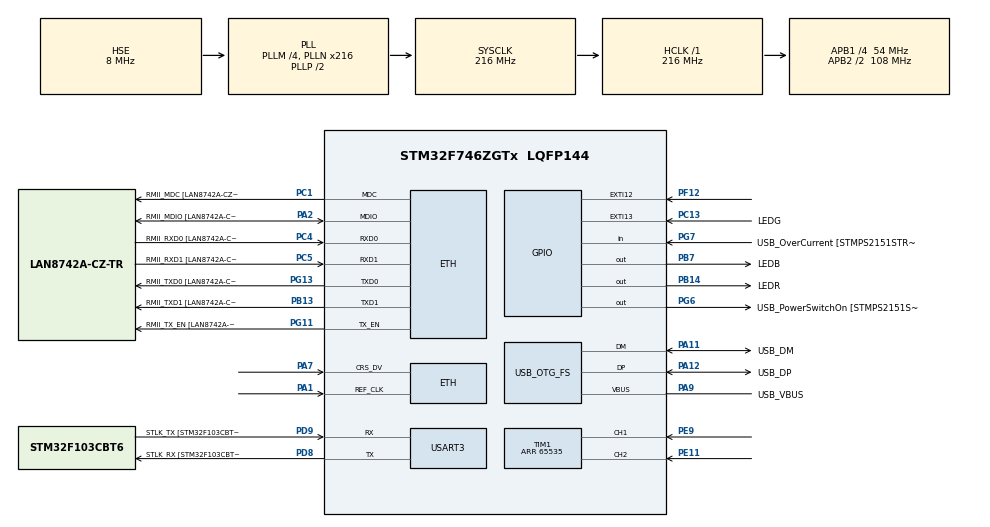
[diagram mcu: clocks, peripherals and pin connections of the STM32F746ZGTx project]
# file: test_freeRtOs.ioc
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CORTEX_M7.ART_ACCLERATOR_ENABLE=1
CORTEX_M7.CPU_DCache=Enabled
CORTEX_M7.CPU_ICache=Enabled
CORTEX_M7.MPU_Control=__NULL
CORTEX_M7.PREFETCH_ENABLE=1
Dma.Request0=USART3_RX
Dma.USART3_RX.0.Direction=DMA_PERIPH_TO_MEMORY
Dma.USART3_RX.0.FIFOMode=DMA_FIFOMODE_DISABLE
Dma.USART3_RX.0.Instance=DMA1_Stream1
Dma.USART3_RX.0.MemDataAlignment=DMA_MDATAALIGN_BYTE
Dma.USART3_RX.0.MemInc=DMA_MINC_ENABLE
Dma.USART3_RX.0.Mode=DMA_NORMAL
Dma.USART3_RX.0.PeriphDataAlignment=DMA_PDATAALIGN_BYTE
Dma.USART3_RX.0.PeriphInc=DMA_PINC_DISABLE
Dma.USART3_RX.0.Priority=DMA_PRIORITY_LOW
ETH.MediaInterface=ETH_MEDIA_INTERFACE_RMII
ETH.PhyAddress=0
FREERTOS.HEAP_NUMBER=3
FREERTOS.INCLUDE_vTaskDelayUntil=1
FREERTOS.MEMORY_ALLOCATION=0
FREERTOS.Queues01=RxUartQueue,1,uint16_t,0,Dynamic,NULL,NULL
FREERTOS.Tasks01=idle,-3,512,idle_start,Default,NULL,Dynamic,NULL,NULL;asserv_task,3,512,start_asserv_task,As external,NULL,Dynamic,NULL,NULL;background_task,-2,512,start_background_task,As external,NULL,Dynamic,NULL,NULL;io_task,1,512,start_io_task,As external,NULL,Dynamic,NULL,NULL
FREERTOS.configCHECK_FOR_STACK_OVERFLOW=2
FREERTOS.configIDLE_SHOULD_YIELD=0
FREERTOS.configTOTAL_HEAP_SIZE=131072
LWIP.CHECKSUM_BY_HARDWARE=1
LWIP.CHECKSUM_CHECK_ICMP=1
LWIP.CHECKSUM_CHECK_ICMP6=1
LWIP.CHECKSUM_CHECK_IP=1
LWIP.CHECKSUM_CHECK_UDP=1
LWIP.CHECKSUM_GEN_ICMP=1
LWIP.CHECKSUM_GEN_ICMP6=1
LWIP.CHECKSUM_GEN_IP=1
LWIP.CHECKSUM_GEN_UDP=1
LWIP.ICMP_DEBUG=LWIP_DBG_ON
LWIP.IP_ADDRESS=192.168.010.002
LWIP.LWIP_DBG_MIN_LEVEL=LWIP_DBG_LEVEL_WARNING
LWIP.LWIP_DHCP=0
LWIP.LWIP_TCP=0
LWIP.MEMP_NUM_RAW_PCB=2
LWIP.MEMP_NUM_TCP_PCB=1
LWIP.MEMP_NUM_TCP_PCB_LISTEN=2
LWIP.MEMP_NUM_UDP_PCB=2
LWIP.MEM_SIZE=4096
LWIP.NETMASK_ADDRESS=255.255.255.000
LWIP.Version=v2.0.3_Cube
Mcu.Family=STM32F7
Mcu.Name=STM32F746ZGTx
Mcu.Package=LQFP144
NVIC.DMA1_Stream1_IRQn=true\:5\:0\:false\:false\:true\:true\:false
NVIC.ETH_IRQn=true\:5\:0\:false\:false\:true\:true\:true
NVIC.ETH_WKUP_IRQn=true\:5\:0\:false\:false\:true\:true\:true
NVIC.OTG_FS_IRQn=true\:5\:0\:false\:false\:true\:true\:false
NVIC.PriorityGroup=NVIC_PRIORITYGROUP_4
NVIC.TIM1_TRG_COM_TIM11_IRQn=true\:0\:0\:false\:false\:true\:false\:false
NVIC.TimeBase=TIM1_TRG_COM_TIM11_IRQn
NVIC.TimeBaseIP=TIM11
NVIC.USART3_IRQn=true\:5\:0\:false\:false\:true\:true\:true
PA1.Mode=RMII
PA1.Signal=ETH_REF_CLK
PA10.GPIO_Label=USB_ID
PA10.Signal=USB_OTG_FS_ID
PA11.GPIO_Label=USB_DM
PA11.Mode=Host_Only
PA11.Signal=USB_OTG_FS_DM
PA12.GPIO_Label=USB_DP
PA12.Mode=Host_Only
PA12.Signal=USB_OTG_FS_DP
PA13.GPIO_Label=TMS
PA13.Mode=Serial_Wire
PA13.Signal=SYS_JTMS-SWDIO
PA14.GPIO_Label=TCK
PA14.Mode=Serial_Wire
PA14.Signal=SYS_JTCK-SWCLK
PA2.GPIO_Label=RMII_MDIO [LAN8742A-CZ-TR_MDIO]
PA2.Mode=RMII
PA2.Signal=ETH_MDIO
PA7.Mode=RMII
PA7.Signal=ETH_CRS_DV
PA8.GPIO_Label=USB_SOF [TP1]
PA8.Signal=USB_OTG_FS_SOF
PA9.GPIO_Label=USB_VBUS
PA9.Mode=Activate_VBUS
PA9.Signal=USB_OTG_FS_VBUS
PB13.GPIO_Label=RMII_TXD1 [LAN8742A-CZ-TR_TXD1]
PB13.Mode=RMII
PB13.Signal=ETH_TXD1
PB14.GPIO_Label=LEDR
PB14.Signal=GPIO_Output
PB3.GPIO_Label=SW0
PB3.Signal=SYS_JTDO-SWO
PB7.GPIO_Label=LEDB
PB7.Signal=GPIO_Output
PC0.Signal=FMC_SDNWE
PC1.GPIO_Label=RMII_MDC [LAN8742A-CZ-TR_MDC]
PC1.Mode=RMII
PC1.Signal=ETH_MDC
PC13.GPIO_Label=LEDG
PC13.Signal=GPXTI13
PC14/OSC32_IN.Mode=LSE-External-Oscillator
PC14/OSC32_IN.Signal=RCC_OSC32_IN
PC15/OSC32_OUT.Mode=LSE-External-Oscillator
PC15/OSC32_OUT.Signal=RCC_OSC32_OUT
PC4.GPIO_Label=RMII_RXD0 [LAN8742A-CZ-TR_RXD0]
PC4.Mode=RMII
PC4.Signal=ETH_RXD0
PC5.GPIO_Label=RMII_RXD1 [LAN8742A-CZ-TR_RXD1]
PC5.Mode=RMII
PC5.Signal=ETH_RXD1
PD8.GPIO_Label=STLK_RX [STM32F103CBT6_PA3]
PD8.Mode=Asynchronous
PD8.Signal=USART3_TX
PD9.GPIO_Label=STLK_TX [STM32F103CBT6_PA2]
PD9.Mode=Asynchronous
PD9.Signal=USART3_RX
PE11.GPIO_PuPd=GPIO_PULLUP
PE11.GPIO_Speed=GPIO_SPEED_FREQ_VERY_HIGH
PE11.Signal=S_TIM1_CH2
PE9.GPIO_PuPd=GPIO_PULLUP
PE9.GPIO_Speed=GPIO_SPEED_FREQ_VERY_HIGH
PE9.Signal=S_TIM1_CH1
PF12.Signal=GPXTI12
PG11.GPIO_Label=RMII_TX_EN [LAN8742A-CZ-TR_TXEN]
PG11.Mode=RMII
PG11.Signal=ETH_TX_EN
PG13.GPIO_Label=RMII_TXD0 [LAN8742A-CZ-TR_TXD0]
PG13.Mode=RMII
PG13.Signal=ETH_TXD0
PG6.GPIO_Label=USB_PowerSwitchOn [STMPS2151STR_EN]
PG6.Signal=GPIO_Output
PG7.GPIO_Label=USB_OverCurrent [STMPS2151STR_FAULT]
PG7.Signal=GPIO_Input
PH0/OSC_IN.GPIO_Label=MCO [STM32F103CBT6_PA8]
PH0/OSC_IN.Mode=HSE-External-Oscillator
PH0/OSC_IN.Signal=RCC_OSC_IN
PH1/OSC_OUT.Mode=HSE-External-Oscillator
PH1/OSC_OUT.Signal=RCC_OSC_OUT
ProjectManager.HeapSize=0x200
ProjectManager.StackSize=0x400
ProjectManager.TargetToolchain=Makefile
RCC.48MHZClocksFreq_Value=24000000
RCC.AHBFreq_Value=216000000
RCC.APB1CLKDivider=RCC_HCLK_DIV4
RCC.APB1Freq_Value=54000000
RCC.APB1TimFreq_Value=108000000
RCC.APB2CLKDivider=RCC_HCLK_DIV2
RCC.APB2Freq_Value=108000000
RCC.APB2TimFreq_Value=216000000
RCC.CortexFreq_Value=216000000
RCC.HCLKFreq_Value=216000000
RCC.HSE_VALUE=8000000
RCC.HSI_VALUE=16000000
RCC.PLLM=4
RCC.PLLMUL=RCC_PLL_MUL9
RCC.PLLN=216
RCC.PLLQ=9
RCC.PRESCALERUSB=RCC_USBCLKSOURCE_PLL_DIV1_5
RCC.SYSCLKFreq_VALUE=216000000
RCC.SYSCLKSource=RCC_SYSCLKSOURCE_PLLCLK
RCC.SYSCLKSourceVirtual=RCC_SYSCLKSOURCE_PLLCLK
RCC.USBFreq_Value=48000000
RCC.VCOOutputFreq_Value=432000000
SH.FMC_SDNWE.0=FMC_SDNWE
SH.S_TIM1_CH1.0=TIM1_CH1,Encoder_Interface
SH.S_TIM1_CH2.0=TIM1_CH2,Encoder_Interface
TIM1.AutoReloadPreload=TIM_AUTORELOAD_PRELOAD_DISABLE
TIM1.EncoderMode=TIM_ENCODERMODE_TI12
TIM1.IC1Filter=15
TIM1.IC2Filter=15
TIM1.Period=65535
TIM1.RepetitionCounter=65535
USART3.VirtualMode-Asynchronous=VM_ASYNC
USART3.WordLength=WORDLENGTH_8B
USB_HOST.BSP.number=1
USB_HOST.USBH_HandleTypeDef-MSC_FS=hUsbHostFS
USB_HOST.VirtualModeFS=Msc
USB_HOST0.BSP.STBoard=false
USB_HOST0.BSP.api=UnknownBspDriver
USB_HOST0.BSP.i2caddr=0
USB_HOST0.BSP.i2creg=0
USB_HOST0.BSP.instance=PB14
USB_HOST0.BSP.ip=GPIO
USB_HOST0.BSP.mode=Output
USB_HOST0.BSP.name=Drive_VBUS_FS
USB_HOST0.BSP.solution=PB14
USB_OTG_FS.VirtualMode=Host_Only
USB_OTG_FS.phy_itface=HCD_PHY_EMBEDDED
VP_FATFS_VS_USB.Mode=USB
VP_FREERTOS_VS_ENABLE.Mode=Enabled
VP_LWIP_VS_Enabled.Mode=Enabled
VP_SYS_VS_tim11.Mode=TIM11
VP_TIM1_VS_OPM.Mode=OPM_bit
VP_USB_HOST_VS_USB_HOST_MSC_FS.Mode=MSC_FS
board=NUCLEO-F746ZG

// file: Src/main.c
/**
  ******************************************************************************
  * @file           : main.c
  * @brief          : Main program body
  ******************************************************************************
  * This notice applies to any and all portions of this file
  * that are not between comment pairs USER CODE BEGIN and
  * USER CODE END. Other portions of this file, whether
  * inserted by the user or by software development tools
  * are owned by their respective copyright owners.
  *
  * Copyright (c) 2018 STMicroelectronics International N.V.
  * All rights reserved.
  *
  * Redistribution and use in source and binary forms, with or without
  * modification, are permitted, provided that the following conditions are met:
  *
  * 1. Redistribution of source code must retain the above copyright notice,
  *    this list of conditions and the following disclaimer.
  * 2. Redistributions in binary form must reproduce the above copyright notice,
  *    this list of conditions and the following disclaimer in the documentation
  *    and/or other materials provided with the distribution.
  * 3. Neither the name of STMicroelectronics nor the names of other
  *    contributors to this software may be used to endorse or promote products
  *    derived from this software without specific written permission.
  * 4. This software, including modifications and/or derivative works of this
  *    software, must execute solely and exclusively on microcontroller or
  *    microprocessor devices manufactured by or for STMicroelectronics.
  * 5. Redistribution and use of this software other than as permitted under
  *    this license is void and will automatically terminate your rights under
  *    this license.
  *
  * THIS SOFTWARE IS PROVIDED BY STMICROELECTRONICS AND CONTRIBUTORS "AS IS"
  * AND ANY EXPRESS, IMPLIED OR STATUTORY WARRANTIES, INCLUDING, BUT NOT
  * LIMITED TO, THE IMPLIED WARRANTIES OF MERCHANTABILITY, FITNESS FOR A
  * PARTICULAR PURPOSE AND NON-INFRINGEMENT OF THIRD PARTY INTELLECTUAL PROPERTY
  * RIGHTS ARE DISCLAIMED TO THE FULLEST EXTENT PERMITTED BY LAW. IN NO EVENT
  * SHALL STMICROELECTRONICS OR CONTRIBUTORS BE LIABLE FOR ANY DIRECT, INDIRECT,
  * INCIDENTAL, SPECIAL, EXEMPLARY, OR CONSEQUENTIAL DAMAGES (INCLUDING, BUT NOT
  * LIMITED TO, PROCUREMENT OF SUBSTITUTE GOODS OR SERVICES; LOSS OF USE, DATA,
  * OR PROFITS; OR BUSINESS INTERRUPTION) HOWEVER CAUSED AND ON ANY THEORY OF
  * LIABILITY, WHETHER IN CONTRACT, STRICT LIABILITY, OR TORT (INCLUDING
  * NEGLIGENCE OR OTHERWISE) ARISING IN ANY WAY OUT OF THE USE OF THIS SOFTWARE,
  * EVEN IF ADVISED OF THE POSSIBILITY OF SUCH DAMAGE.
  *
  ******************************************************************************
  */
#include "main.h"
#include "stm32f7xx_hal.h"
#include "cmsis_os.h"
#include "dma.h"
#include "lwip.h"
#include "tim.h"
#include "usart.h"
#include "usb_otg.h"
#include "gpio.h"

/* USER CODE BEGIN Includes */
#include "usart.h"
/* USER CODE END Includes */

/* USER CODE BEGIN PV */
/* Private variables ---------------------------------------------------------*/

/* USER CODE END PV */

void SystemClock_Config(void);
void MX_FREERTOS_Init(void);

/* USER CODE BEGIN PFP */
/* Private function prototypes -----------------------------------------------*/

/* USER CODE END PFP */

int main(void)
{

  /* Enable I-Cache-------------------------------------------------------------*/
  SCB_EnableICache();

  /* Enable D-Cache-------------------------------------------------------------*/
  SCB_EnableDCache();

  /* MCU Configuration----------------------------------------------------------*/

  /* Reset of all peripherals, Initializes the Flash interface and the Systick. */
  HAL_Init();

  /* Configure the system clock */
  SystemClock_Config();

  /* Initialize all configured peripherals */
  MX_GPIO_Init();
  MX_DMA_Init();
  MX_USART3_UART_Init();
  MX_TIM1_Init();
  MX_USB_OTG_FS_PCD_Init();
  /* USER CODE BEGIN 2 */

//  __HAL_UART_ENABLE_IT(&huart3, UART_IT_RXNE);
  __HAL_UART_ENABLE_IT(&huart3, UART_IT_TC);

  HAL_NVIC_EnableIRQ(ETH_IRQn);

  /* Enable ETHERNET clock  */
  __HAL_RCC_ETH_CLK_ENABLE();
  __HAL_RCC_ETHMAC_CLK_ENABLE();
  __HAL_RCC_ETHMACTX_CLK_ENABLE();
  __HAL_RCC_ETHMACRX_CLK_ENABLE();

  /* USER CODE END 2 */

  /* Call init function for freertos objects (in freertos.c) */
  MX_FREERTOS_Init();

  /* Start scheduler */
  osKernelStart();

  /* We should never get here as control is now taken by the scheduler */

  /* Infinite loop */
  while (1)
  {

  }

}

void SystemClock_Config(void)
{

  RCC_OscInitTypeDef RCC_OscInitStruct;
  RCC_ClkInitTypeDef RCC_ClkInitStruct;
  RCC_PeriphCLKInitTypeDef PeriphClkInitStruct;

    /**Configure the main internal regulator output voltage
    */
  __HAL_RCC_PWR_CLK_ENABLE();

  __HAL_PWR_VOLTAGESCALING_CONFIG(PWR_REGULATOR_VOLTAGE_SCALE1);

    /**Initializes the CPU, AHB and APB busses clocks
    */
  RCC_OscInitStruct.OscillatorType = RCC_OSCILLATORTYPE_HSE;
  RCC_OscInitStruct.HSEState = RCC_HSE_BYPASS;
  RCC_OscInitStruct.PLL.PLLState = RCC_PLL_ON;
  RCC_OscInitStruct.PLL.PLLSource = RCC_PLLSOURCE_HSE;
  RCC_OscInitStruct.PLL.PLLM = 4;
  RCC_OscInitStruct.PLL.PLLN = 216;
  RCC_OscInitStruct.PLL.PLLP = RCC_PLLP_DIV2;
  RCC_OscInitStruct.PLL.PLLQ = 9;
  if (HAL_RCC_OscConfig(&RCC_OscInitStruct) != HAL_OK)
  {
    _Error_Handler(__FILE__, __LINE__);
  }

    /**Activate the Over-Drive mode
    */
  if (HAL_PWREx_EnableOverDrive() != HAL_OK)
  {
    _Error_Handler(__FILE__, __LINE__);
  }

    /**Initializes the CPU, AHB and APB busses clocks
    */
  RCC_ClkInitStruct.ClockType = RCC_CLOCKTYPE_HCLK|RCC_CLOCKTYPE_SYSCLK
                              |RCC_CLOCKTYPE_PCLK1|RCC_CLOCKTYPE_PCLK2;
  RCC_ClkInitStruct.SYSCLKSource = RCC_SYSCLKSOURCE_PLLCLK;
  RCC_ClkInitStruct.AHBCLKDivider = RCC_SYSCLK_DIV1;
  RCC_ClkInitStruct.APB1CLKDivider = RCC_HCLK_DIV4;
  RCC_ClkInitStruct.APB2CLKDivider = RCC_HCLK_DIV2;

  if (HAL_RCC_ClockConfig(&RCC_ClkInitStruct, FLASH_LATENCY_7) != HAL_OK)
  {
    _Error_Handler(__FILE__, __LINE__);
  }

  PeriphClkInitStruct.PeriphClockSelection = RCC_PERIPHCLK_USART3|RCC_PERIPHCLK_CLK48;
  PeriphClkInitStruct.Usart3ClockSelection = RCC_USART3CLKSOURCE_PCLK1;
  PeriphClkInitStruct.Clk48ClockSelection = RCC_CLK48SOURCE_PLL;
  if (HAL_RCCEx_PeriphCLKConfig(&PeriphClkInitStruct) != HAL_OK)
  {
    _Error_Handler(__FILE__, __LINE__);
  }

    /**Configure the Systick interrupt time
    */
  HAL_SYSTICK_Config(HAL_RCC_GetHCLKFreq()/1000);

    /**Configure the Systick
    */
  HAL_SYSTICK_CLKSourceConfig(SYSTICK_CLKSOURCE_HCLK);

  /* SysTick_IRQn interrupt configuration */
  HAL_NVIC_SetPriority(SysTick_IRQn, 15, 0);
}

void HAL_TIM_PeriodElapsedCallback(TIM_HandleTypeDef *htim)
{
  if (htim->Instance == TIM11) {
    HAL_IncTick();
  }
}

void _Error_Handler(char *file, int line)
{
  while(1)
  {
  }
}

/************************ (C) COPYRIGHT STMicroelectronics *****END OF FILE****/

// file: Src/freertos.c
/**
  ******************************************************************************
  * File Name          : freertos.c
  * Description        : Code for freertos applications
  ******************************************************************************
  * This notice applies to any and all portions of this file
  * that are not between comment pairs USER CODE BEGIN and
  * USER CODE END. Other portions of this file, whether
  * inserted by the user or by software development tools
  * are owned by their respective copyright owners.
  *
  * Copyright (c) 2018 STMicroelectronics International N.V.
  * All rights reserved.
  *
  * Redistribution and use in source and binary forms, with or without
  * modification, are permitted, provided that the following conditions are met:
  *
  * 1. Redistribution of source code must retain the above copyright notice,
  *    this list of conditions and the following disclaimer.
  * 2. Redistributions in binary form must reproduce the above copyright notice,
  *    this list of conditions and the following disclaimer in the documentation
  *    and/or other materials provided with the distribution.
  * 3. Neither the name of STMicroelectronics nor the names of other
  *    contributors to this software may be used to endorse or promote products
  *    derived from this software without specific written permission.
  * 4. This software, including modifications and/or derivative works of this
  *    software, must execute solely and exclusively on microcontroller or
  *    microprocessor devices manufactured by or for STMicroelectronics.
  * 5. Redistribution and use of this software other than as permitted under
  *    this license is void and will automatically terminate your rights under
  *    this license.
  *
  * THIS SOFTWARE IS PROVIDED BY STMICROELECTRONICS AND CONTRIBUTORS "AS IS"
  * AND ANY EXPRESS, IMPLIED OR STATUTORY WARRANTIES, INCLUDING, BUT NOT
  * LIMITED TO, THE IMPLIED WARRANTIES OF MERCHANTABILITY, FITNESS FOR A
  * PARTICULAR PURPOSE AND NON-INFRINGEMENT OF THIRD PARTY INTELLECTUAL PROPERTY
  * RIGHTS ARE DISCLAIMED TO THE FULLEST EXTENT PERMITTED BY LAW. IN NO EVENT
  * SHALL STMICROELECTRONICS OR CONTRIBUTORS BE LIABLE FOR ANY DIRECT, INDIRECT,
  * INCIDENTAL, SPECIAL, EXEMPLARY, OR CONSEQUENTIAL DAMAGES (INCLUDING, BUT NOT
  * LIMITED TO, PROCUREMENT OF SUBSTITUTE GOODS OR SERVICES; LOSS OF USE, DATA,
  * OR PROFITS; OR BUSINESS INTERRUPTION) HOWEVER CAUSED AND ON ANY THEORY OF
  * LIABILITY, WHETHER IN CONTRACT, STRICT LIABILITY, OR TORT (INCLUDING
  * NEGLIGENCE OR OTHERWISE) ARISING IN ANY WAY OUT OF THE USE OF THIS SOFTWARE,
  * EVEN IF ADVISED OF THE POSSIBILITY OF SUCH DAMAGE.
  *
  ******************************************************************************
  */

#include "FreeRTOS.h"
#include "task.h"
#include "cmsis_os.h"

osThreadId idleHandle;
osThreadId asserv_taskHandle;
osThreadId background_taskHandle;
osThreadId io_taskHandle;
osMessageQId RxUartQueueHandle;

void idle_start(void const * argument);
extern void start_asserv_task(void const * argument);
extern void start_background_task(void const * argument);
extern void start_io_task(void const * argument);

extern void MX_LWIP_Init(void);
void MX_FREERTOS_Init(void); /* (MISRA C 2004 rule 8.1) */

/* Hook prototypes */
void vApplicationStackOverflowHook(xTaskHandle xTask, signed char *pcTaskName);

/* USER CODE BEGIN 4 */
__attribute__((weak)) void vApplicationStackOverflowHook(xTaskHandle xTask, signed char *pcTaskName)
{
	printf("Stack overflow in task %s \n", pcTaskName);
   /* Run time stack overflow checking is performed if
   configCHECK_FOR_STACK_OVERFLOW is defined to 1 or 2. This hook function is
   called if a stack overflow is detected. */
}
/* USER CODE END 4 */

/* Init FreeRTOS */

void MX_FREERTOS_Init(void) {

  /* Create the thread(s) */
  /* definition and creation of idle */
  osThreadDef(idle, idle_start, osPriorityIdle, 0, 512);
  idleHandle = osThreadCreate(osThread(idle), NULL);

  /* definition and creation of asserv_task */
  osThreadDef(asserv_task, start_asserv_task, osPriorityRealtime, 0, 512);
  asserv_taskHandle = osThreadCreate(osThread(asserv_task), NULL);

  /* definition and creation of background_task */
  osThreadDef(background_task, start_background_task, osPriorityLow, 0, 512);
  background_taskHandle = osThreadCreate(osThread(background_task), NULL);

  /* definition and creation of io_task */
  osThreadDef(io_task, start_io_task, osPriorityAboveNormal, 0, 512);
  io_taskHandle = osThreadCreate(osThread(io_task), NULL);

  /* Create the queue(s) */
  /* definition and creation of RxUartQueue */
  osMessageQDef(RxUartQueue, 1, uint16_t);
  RxUartQueueHandle = osMessageCreate(osMessageQ(RxUartQueue), NULL);

}

/* idle_start function */
void idle_start(void const * argument)
{
  /* init code for LWIP */
//  MX_LWIP_Init();

  /* USER CODE BEGIN idle_start */
  /* Infinite loop */
  for(;;)
  {
    osDelay(10);
  }
  /* USER CODE END idle_start */
}

/************************ (C) COPYRIGHT STMicroelectronics *****END OF FILE****/
